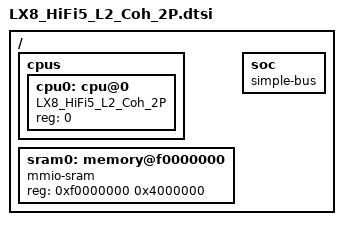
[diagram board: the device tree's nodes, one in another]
/*
 * Copyright (c) 2024 Cadence Design Systems, Inc.
 *
 * SPDX-License-Identifier: Apache-2.0
 */

#include "skeleton.dtsi"

/ {
	cpus {
		#address-cells = <1>;
		#size-cells = <0>;

		cpu0: cpu@0 {
			device_type = "cpu";
			compatible = "LX8_HiFi5_L2_Coh_2P";
			reg = <0>;
		};
	};

	sram0: memory@f0000000 {
		device_type = "memory";
		compatible = "mmio-sram";
		reg = <0xf0000000 0x4000000>;
	};

	soc {
		#address-cells = <1>;
		#size-cells = <1>;
		compatible = "simple-bus";
		ranges;

	};
};
